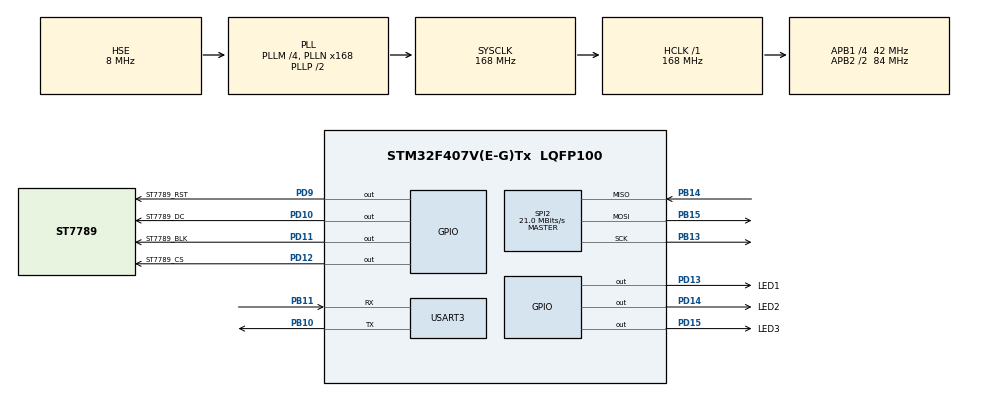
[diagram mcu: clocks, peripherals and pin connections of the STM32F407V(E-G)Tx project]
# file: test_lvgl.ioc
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Mcu.Family=STM32F4
Mcu.Name=STM32F407V(E-G)Tx
Mcu.Package=LQFP100
NVIC.PriorityGroup=NVIC_PRIORITYGROUP_0
PA13.Mode=Serial_Wire
PA13.Signal=SYS_JTMS-SWDIO
PA14.Mode=Serial_Wire
PA14.Signal=SYS_JTCK-SWCLK
PB10.Mode=Asynchronous
PB10.Signal=USART3_TX
PB11.Mode=Asynchronous
PB11.Signal=USART3_RX
PB13.Mode=Full_Duplex_Master
PB13.Signal=SPI2_SCK
PB14.Mode=Full_Duplex_Master
PB14.Signal=SPI2_MISO
PB15.Mode=Full_Duplex_Master
PB15.Signal=SPI2_MOSI
PD10.GPIO_Label=ST7789_DC
PD10.GPIO_Speed=GPIO_SPEED_FREQ_VERY_HIGH
PD10.Signal=GPIO_Output
PD11.GPIO_Label=ST7789_BLK
PD11.GPIO_Speed=GPIO_SPEED_FREQ_VERY_HIGH
PD11.Signal=GPIO_Output
PD12.GPIO_Label=ST7789_CS
PD12.GPIO_Speed=GPIO_SPEED_FREQ_VERY_HIGH
PD12.Signal=GPIO_Output
PD13.GPIO_Label=LED1
PD13.GPIO_Speed=GPIO_SPEED_FREQ_VERY_HIGH
PD13.Signal=GPIO_Output
PD14.GPIO_Label=LED2
PD14.GPIO_Speed=GPIO_SPEED_FREQ_VERY_HIGH
PD14.Signal=GPIO_Output
PD15.GPIO_Label=LED3
PD15.GPIO_Speed=GPIO_SPEED_FREQ_VERY_HIGH
PD15.Signal=GPIO_Output
PD9.GPIO_Label=ST7789_RST
PD9.GPIO_Speed=GPIO_SPEED_FREQ_VERY_HIGH
PD9.Signal=GPIO_Output
PH0-OSC_IN.Mode=HSE-External-Oscillator
PH0-OSC_IN.Signal=RCC_OSC_IN
PH1-OSC_OUT.Mode=HSE-External-Oscillator
PH1-OSC_OUT.Signal=RCC_OSC_OUT
ProjectManager.HeapSize=0x200
ProjectManager.StackSize=0x400
ProjectManager.TargetToolchain=STM32CubeIDE
RCC.48MHZClocksFreq_Value=48000000
RCC.AHBFreq_Value=168000000
RCC.APB1CLKDivider=RCC_HCLK_DIV4
RCC.APB1Freq_Value=42000000
RCC.APB1TimFreq_Value=84000000
RCC.APB2CLKDivider=RCC_HCLK_DIV2
RCC.APB2Freq_Value=84000000
RCC.APB2TimFreq_Value=168000000
RCC.CortexFreq_Value=168000000
RCC.HCLKFreq_Value=168000000
RCC.HSE_VALUE=8000000
RCC.HSI_VALUE=16000000
RCC.LSE_VALUE=32768
RCC.PLLM=4
RCC.PLLN=168
RCC.PLLQ=7
RCC.PLLSourceVirtual=RCC_PLLSOURCE_HSE
RCC.SYSCLKFreq_VALUE=168000000
RCC.SYSCLKSource=RCC_SYSCLKSOURCE_PLLCLK
RCC.VCOOutputFreq_Value=336000000
SPI2.BaudRatePrescaler=SPI_BAUDRATEPRESCALER_2
SPI2.CalculateBaudRate=21.0 MBits/s
SPI2.Direction=SPI_DIRECTION_2LINES
SPI2.Mode=SPI_MODE_MASTER
SPI2.VirtualType=VM_MASTER
USART3.VirtualMode=VM_ASYNC
board=STM32F407G-DISC1

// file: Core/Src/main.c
/* USER CODE BEGIN Header */
/**
  ******************************************************************************
  * @file           : main.c
  * @brief          : Main program body
  ******************************************************************************
  * @attention
  *
  * <h2><center>&copy; Copyright (c) 2022 STMicroelectronics.
  * All rights reserved.</center></h2>
  *
  * This software component is licensed by ST under Ultimate Liberty license
  * SLA0044, the "License"; You may not use this file except in compliance with
  * the License. You may obtain a copy of the License at:
  *                             www.st.com/SLA0044
  *
  ******************************************************************************
  */
/* USER CODE END Header */

#include "main.h"
#include "spi.h"
#include "usart.h"
#include "gpio.h"

/* USER CODE BEGIN Includes */
#include "../lvgl/lvgl.h"
#include "../lvgl/examples/lv_examples.h"
#include "../drivers/st7789/st7789.h"
#include "../drivers/print/retarget.h"
#include "../drivers/st7789/utility.h"
#include <stdio.h>

int count;
char buf[4];

/* USER CODE END Includes */

void SystemClock_Config(void);

int main(void)
{

  /* MCU Configuration--------------------------------------------------------*/

  /* Reset of all peripherals, Initializes the Flash interface and the Systick. */
  HAL_Init();

  /* Configure the system clock */
  SystemClock_Config();

  /* Initialize all configured peripherals */
  MX_GPIO_Init();
  MX_USART3_UART_Init();
  MX_SPI2_Init();
  /* USER CODE BEGIN 2 */

  lv_init();
  Display_init(0);
  RetargetInit(&huart3);

  //lv_obj_t * arc = lv_arc_create(lv_scr_act());
  //lv_arc_set_rotation(arc, 270);
  //lv_arc_set_bg_angles(arc, 0, 360);
  //lv_obj_remove_style(arc, NULL, LV_PART_KNOB);   /*Be sure the knob is not displayed*/
  //lv_obj_clear_flag(arc, LV_OBJ_FLAG_CLICKABLE);  /*To not allow adjusting by click*/
  //lv_obj_center(arc);
  //
  //lv_anim_t a;
  //lv_anim_init(&a);
  //lv_anim_set_var(&a, arc);
  ////lv_anim_set_exec_cb(&a, set_angle);
  //lv_anim_set_time(&a, 1000);
  //lv_anim_set_repeat_count(&a, LV_ANIM_REPEAT_INFINITE);    /*Just for the demo*/
  //lv_anim_set_repeat_delay(&a, 500);
  //lv_anim_set_values(&a, 0, 100);
  //lv_anim_start(&a);
  //
  //
  //lv_obj_t * label1 = lv_label_create(lv_scr_act());
  //lv_label_set_long_mode(label1, LV_LABEL_LONG_SCROLL_CIRCULAR);     /*Break the long lines*/
  //lv_label_set_recolor(label1, true);                      /*Enable re-coloring by commands in the text*/
  //lv_label_set_text(label1, "00");
  //lv_obj_set_width(label1, 150);  /*Set smaller width to make the lines wrap*/
  //lv_obj_set_style_text_align(label1, LV_TEXT_ALIGN_CENTER, 0);
  //lv_obj_align(label1, LV_ALIGN_CENTER, 0, 0);
  //

  lv_example_meter_1();

  /* USER CODE END 2 */

  /* Infinite loop */
  while (1)
  {

    /* USER CODE BEGIN 3 */
	 HAL_Delay(10);
	 lv_timer_handler();
	// count++;
	// if(count == 101)
	//	 count = 0;
	// sprintf(buf,"%d",count);
	// lv_label_set_text(label1,buf);
	// lv_arc_set_value(arc, count);

  }
  /* USER CODE END 3 */
}

void SystemClock_Config(void)
{
  RCC_OscInitTypeDef RCC_OscInitStruct = {0};
  RCC_ClkInitTypeDef RCC_ClkInitStruct = {0};

  /** Configure the main internal regulator output voltage
  */
  __HAL_RCC_PWR_CLK_ENABLE();
  __HAL_PWR_VOLTAGESCALING_CONFIG(PWR_REGULATOR_VOLTAGE_SCALE1);
  /** Initializes the RCC Oscillators according to the specified parameters
  * in the RCC_OscInitTypeDef structure.
  */
  RCC_OscInitStruct.OscillatorType = RCC_OSCILLATORTYPE_HSE;
  RCC_OscInitStruct.HSEState = RCC_HSE_ON;
  RCC_OscInitStruct.PLL.PLLState = RCC_PLL_ON;
  RCC_OscInitStruct.PLL.PLLSource = RCC_PLLSOURCE_HSE;
  RCC_OscInitStruct.PLL.PLLM = 4;
  RCC_OscInitStruct.PLL.PLLN = 168;
  RCC_OscInitStruct.PLL.PLLP = RCC_PLLP_DIV2;
  RCC_OscInitStruct.PLL.PLLQ = 7;
  if (HAL_RCC_OscConfig(&RCC_OscInitStruct) != HAL_OK)
  {
    Error_Handler();
  }
  /** Initializes the CPU, AHB and APB buses clocks
  */
  RCC_ClkInitStruct.ClockType = RCC_CLOCKTYPE_HCLK|RCC_CLOCKTYPE_SYSCLK
                              |RCC_CLOCKTYPE_PCLK1|RCC_CLOCKTYPE_PCLK2;
  RCC_ClkInitStruct.SYSCLKSource = RCC_SYSCLKSOURCE_PLLCLK;
  RCC_ClkInitStruct.AHBCLKDivider = RCC_SYSCLK_DIV1;
  RCC_ClkInitStruct.APB1CLKDivider = RCC_HCLK_DIV4;
  RCC_ClkInitStruct.APB2CLKDivider = RCC_HCLK_DIV2;

  if (HAL_RCC_ClockConfig(&RCC_ClkInitStruct, FLASH_LATENCY_5) != HAL_OK)
  {
    Error_Handler();
  }
}

void Error_Handler(void)
{
  __disable_irq();
  while (1)
  {
  }
}
